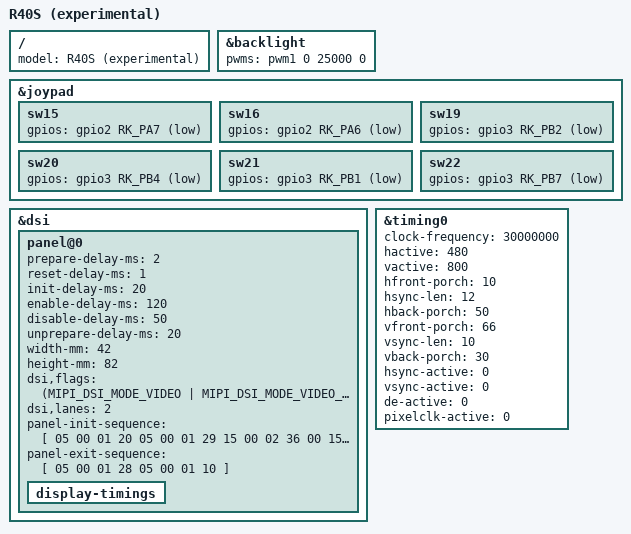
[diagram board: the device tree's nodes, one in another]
// SPDX-License-Identifier: (GPL-2.0+ OR MIT)
/*
 * EXPERIMENTAL - not tested on hardware by andr36oid. Keep a copy of the
 * files you replace so you can go back.
 *
 * R40S (arkos4clone "r40s"): genuine R36S wiring (same PMIC pins, rails,
 * SD slots), 480x800 two-lane panel mounted sideways, backlight period
 * 25000. Shoulder and Select/Start buttons sit on other pins (stock DTB):
 * L1 GPIO2_A7, R1 GPIO2_A6, L2 GPIO3_B1, R2 GPIO3_B4, Select GPIO3_B2,
 * Start GPIO3_B7. All six pins are already in the R36S button pin group.
 * Boot with androidboot.sf_orientation=ORIENTATION_270 fbcon=rotate:3
 * (stock boot.ini has fbcon=rotate:3).
 *
 * Panel values (delays, size, flags, init and exit sequence, timing) are
 * copied from the reference DTB:
 *   lcdyk0517/arkos4clone @2656e5b6, boot/dArkOS/consoles/r40s
 *   init sequence 164 bytes, md5 594f7e3cfba8
 */

/dts-v1/;

#include "rk3326-r36s-android.dtsi"

/ {
	model = "R40S (experimental)";
};

&backlight {
	pwms = <&pwm1 0 25000 0>;
};

&joypad {
	sw15 {
		gpios = <&gpio2 RK_PA7 GPIO_ACTIVE_LOW>;	/* L1 */
	};
	sw16 {
		gpios = <&gpio2 RK_PA6 GPIO_ACTIVE_LOW>;	/* R1 */
	};
	sw19 {
		gpios = <&gpio3 RK_PB2 GPIO_ACTIVE_LOW>;	/* Select */
	};
	sw20 {
		gpios = <&gpio3 RK_PB4 GPIO_ACTIVE_LOW>;	/* R2 */
	};
	sw21 {
		gpios = <&gpio3 RK_PB1 GPIO_ACTIVE_LOW>;	/* L2 */
	};
	sw22 {
		gpios = <&gpio3 RK_PB7 GPIO_ACTIVE_LOW>;	/* Start */
	};
};

&dsi {
	panel@0 {
		prepare-delay-ms = <2>;
		reset-delay-ms = <1>;
		init-delay-ms = <20>;
		enable-delay-ms = <120>;
		disable-delay-ms = <50>;
		unprepare-delay-ms = <20>;
		width-mm = <42>;
		height-mm = <82>;
		dsi,flags = <(MIPI_DSI_MODE_VIDEO |
		      MIPI_DSI_MODE_VIDEO_BURST |
		      MIPI_DSI_MODE_EOT_PACKET |
		      MIPI_DSI_MODE_LPM)>;
		dsi,lanes = <2>;
		panel-init-sequence = [
			05 00 01 20
			05 00 01 29
			15 00 02 36 00
			15 00 02 3a 70
			39 00 04 b1 06 05 0a
			39 00 03 b2 20 c8
			15 00 02 b3 02
			15 00 02 b5 40
			39 00 07 b6 07 0f 02 40 10 e8
			39 00 06 c3 07 04 03 03 02
			39 00 07 c4 12 24 18 18 02 49
			15 00 02 c5 69
			39 00 04 c6 41 63 03
			39 00 0a d0 00 24 67 02 00 00 20 00 02
			39 00 0a d1 00 24 67 02 00 00 20 00 02
			39 00 0a d2 00 24 67 02 00 00 20 00 02
			39 00 0a d3 00 24 67 02 00 00 20 00 02
			39 00 0a d4 00 24 67 02 00 00 20 00 02
			39 00 0a d5 00 24 67 02 00 00 20 00 02
			05 c8 01 11
		];
		panel-exit-sequence = [
			05 00 01 28
			05 00 01 10
		];
		display-timings {
			/* one mode only: the R36S alternates do not fit this panel */
			/delete-node/ timing1;
			/delete-node/ timing2;
		};
	};
};

&timing0 {
	clock-frequency = <30000000>;
	hactive = <480>;
	vactive = <800>;
	hfront-porch = <10>;
	hsync-len = <12>;
	hback-porch = <50>;
	vfront-porch = <66>;	/* stock value, 59.99 Hz */
	vsync-len = <10>;
	vback-porch = <30>;
	hsync-active = <0>;
	vsync-active = <0>;
	de-active = <0>;
	pixelclk-active = <0>;
};
